# STM32L562xx register map
File version: 1.0
Registers are 32-bit, read-write, reset 0x0 unless marked. A register's access mark holds for its fields unless they carry their own. Offsets are from the block's base; [hi:lo] are bit positions; {n}, {i} and the like mark numbered series; 'fields as' and 'values as' point back to an identical list.

## FMC_Bank1_R — Flexible Memory Controller
Base 0x44020000
Same registers: FMC_Bank1_R_S 0x54020000
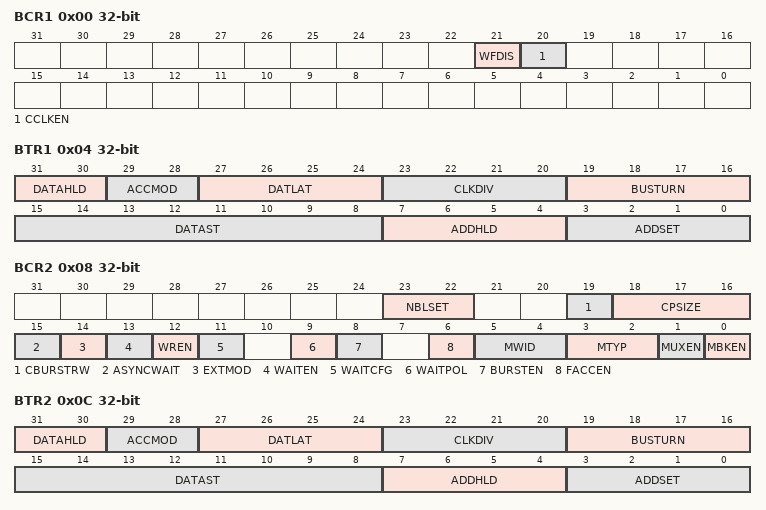
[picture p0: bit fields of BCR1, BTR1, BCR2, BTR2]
0x00 BCR1 — NOR/PSRAM chip-select control register(BCR) and chip-select timing register(BTR)
  [21] WFDIS — Write FIFO Disable
  [20] CCLKEN — Continuous clock enable
0x04 BTR1 — NOR/PSRAM chip-select control register(BCR) and chip-select timing register(BTR)
  [31:30] DATAHLD — DATAHLD[1:0] bits (Data hold phase duration)
  [29:28] ACCMOD — ACCMOD[1:0] bits (Access mode)
  [27:24] DATLAT — DATLAT[3:0] bits (Data latency)
  [23:20] CLKDIV — CLKDIV[3:0] bits (Clock divide ratio)
  [19:16] BUSTURN — BUSTURN[3:0] bits (Bus turnaround phase duration)
  [15:8] DATAST — DATAST [3:0] bits (Data-phase duration)
  [7:4] ADDHLD — ADDHLD[3:0] bits (Address-hold phase duration)
  [3:0] ADDSET — ADDSET[3:0] bits (Address setup phase duration)
0x08 BCR2 — NOR/PSRAM chip-select control register(BCR) and chip-select timing register(BTR)
  [23:22] NBLSET — Byte lane (NBL) setup
  [19] CBURSTRW — Write burst enable
  [18:16] CPSIZE — CRAM page size
  [15] ASYNCWAIT — Asynchronous wait
  [14] EXTMOD — Extended mode enable
  [13] WAITEN — Wait enable bit
  [12] WREN — Write enable bit
  [11] WAITCFG — Wait timing configuration
  [9] WAITPOL — Wait signal polarity bit
  [8] BURSTEN — Burst enable bit
  [6] FACCEN — Flash access enable
  [5:4] MWID — MWID[1:0] bits (Memory data bus width)
  [3:2] MTYP — MTYP[1:0] bits (Memory type)
  [1] MUXEN — Address/data multiplexing enable bit
  [0] MBKEN — Memory bank enable bit
0x0C BTR2 — NOR/PSRAM chip-select control register(BCR) and chip-select timing register(BTR)
  fields as BTR1
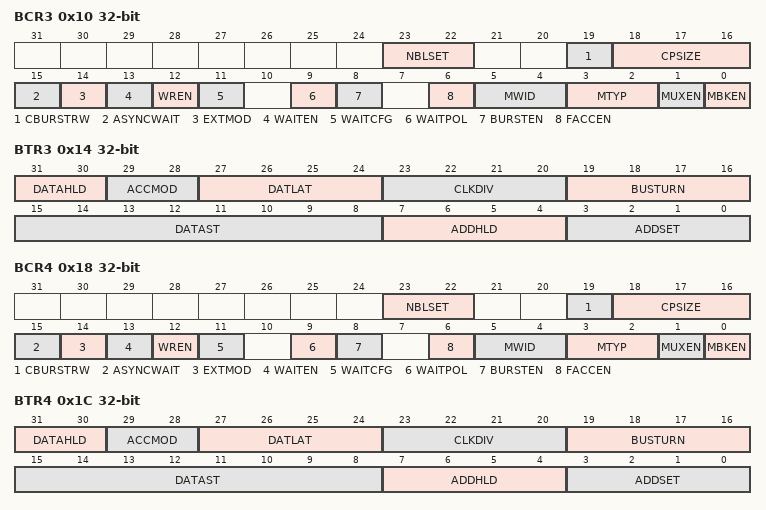
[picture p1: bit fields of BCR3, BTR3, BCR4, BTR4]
0x10 BCR3 — NOR/PSRAM chip-select control register(BCR) and chip-select timing register(BTR)
  fields as BCR2
0x14 BTR3 — NOR/PSRAM chip-select control register(BCR) and chip-select timing register(BTR)
  fields as BTR1
0x18 BCR4 — NOR/PSRAM chip-select control register(BCR) and chip-select timing register(BTR)
  fields as BCR2
0x1C BTR4 — NOR/PSRAM chip-select control register(BCR) and chip-select timing register(BTR)
  fields as BTR1
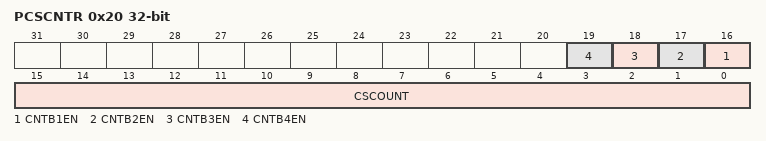
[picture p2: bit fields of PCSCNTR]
0x20 PCSCNTR — PSRAM chip-select counter register
  [n+15] CNTB{n}EN (n=1..4) — Counter PSRAM/NOR Bank1_{n} enable
  [15:0] CSCOUNT — CSCOUNT[15:0] bits (Chip select counter)

## FMC_Bank3_R — Flexible Memory Controller Bank3
Base 0x44020080
Same registers: FMC_Bank3_R_S 0x54020080
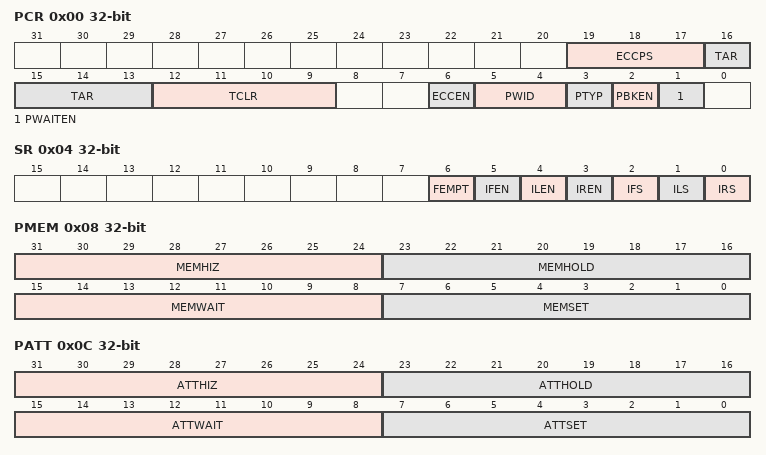
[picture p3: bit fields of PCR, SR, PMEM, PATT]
0x00 PCR — NAND Flash control register
  [19:17] ECCPS — ECCPS[1:0] bits (ECC page size)
  [16:13] TAR — TAR[3:0] bits (ALE to RE delay)
  [12:9] TCLR — TCLR[3:0] bits (CLE to RE delay)
  [6] ECCEN — ECC computation logic enable bit
  [5:4] PWID — PWID[1:0] bits (NAND Flash databus width)
  [3] PTYP — Memory type
  [2] PBKEN — NAND Flash memory bank enable bit
  [1] PWAITEN — Wait feature enable bit
0x04 SR — NAND Flash FIFO status and interrupt register
  [6] FEMPT — FIFO empty
  [5] IFEN — Interrupt Falling Edge detection Enable bit
  [4] ILEN — Interrupt Level detection Enable bit
  [3] IREN — Interrupt Rising Edge detection Enable bit
  [2] IFS — Interrupt Falling Edge status
  [1] ILS — Interrupt Level status
  [0] IRS — Interrupt Rising Edge status
0x08 PMEM — NAND Flash Common memory space timing register
  [31:24] MEMHIZ — MEMHIZ[7:0] bits (Common memory databus HiZ time)
  [23:16] MEMHOLD — MEMHOLD[7:0] bits (Common memory hold time)
  [15:8] MEMWAIT — MEMWAIT[7:0] bits (Common memory wait time)
  [7:0] MEMSET — MEMSET[7:0] bits (Common memory setup time)
0x0C PATT — NAND Flash Attribute memory space timing register
  [31:24] ATTHIZ — ATTHIZ[7:0] bits (Attribute memory databus HiZ time)
  [23:16] ATTHOLD — ATTHOLD[7:0] bits (Attribute memory hold time)
  [15:8] ATTWAIT — ATTWAIT[7:0] bits (Attribute memory wait time)
  [7:0] ATTSET — ATTSET[7:0] bits (Attribute memory setup time)
0x14 ECCR — NAND Flash ECC result registers
  [31:0] ECC — ECC result

## FMC_Bank1E_R — Flexible Memory Controller Bank1E
Base 0x44020104
Same registers: FMC_Bank1E_R_S 0x54020104
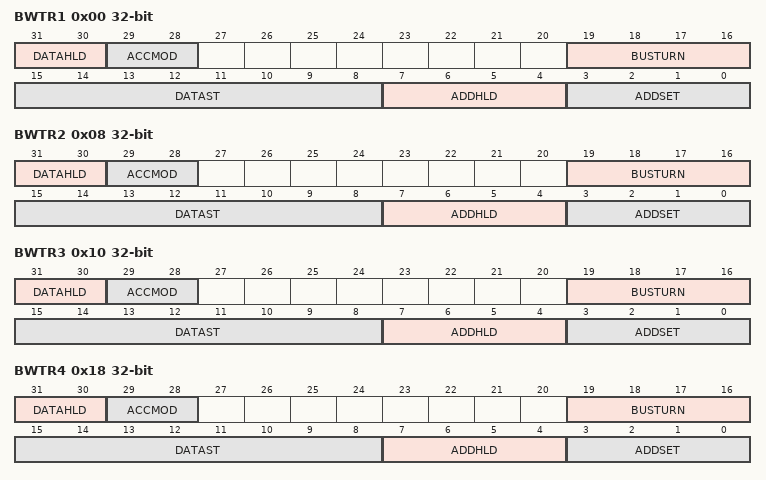
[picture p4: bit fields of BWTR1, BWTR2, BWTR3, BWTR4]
0x00 BWTR1 — NOR/PSRAM write timing registers
  [31:30] DATAHLD — DATAHLD[1:0] bits (Data hold phase duration)
  [29:28] ACCMOD — ACCMOD[1:0] bits (Access mode)
  [19:16] BUSTURN — BUSTURN[3:0] bits (Bus turnaround phase duration)
  [15:8] DATAST — DATAST [3:0] bits (Data-phase duration)
  [7:4] ADDHLD — ADDHLD[3:0] bits (Address-hold phase duration)
  [3:0] ADDSET — ADDSET[3:0] bits (Address setup phase duration)
0x08 BWTR2 — NOR/PSRAM write timing registers
  fields as BWTR1
0x10 BWTR3 — NOR/PSRAM write timing registers
  fields as BWTR1
0x18 BWTR4 — NOR/PSRAM write timing registers
  fields as BWTR1

## DBGMCU — Debug MCU
Base 0xE0044000
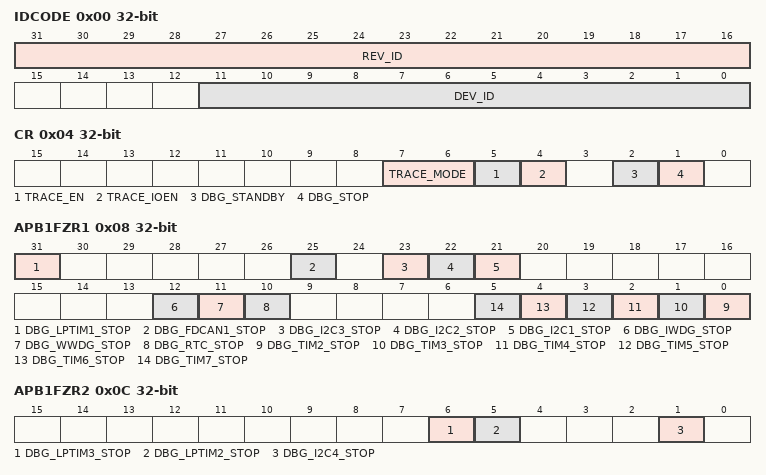
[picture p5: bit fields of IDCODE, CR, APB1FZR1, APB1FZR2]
0x00 IDCODE — MCU device ID code
  [31:16] REV_ID, [11:0] DEV_ID
0x04 CR — Debug MCU configuration register
  [7:6] TRACE_MODE, [5] TRACE_EN, [4] TRACE_IOEN, [2] DBG_STANDBY, [1] DBG_STOP
0x08 APB1FZR1 — Debug MCU APB1 freeze register 1
  [31] DBG_LPTIM1_STOP, [25] DBG_FDCAN1_STOP, [23] DBG_I2C3_STOP, [22] DBG_I2C2_STOP, [21] DBG_I2C1_STOP, [12] DBG_IWDG_STOP, [11] DBG_WWDG_STOP, [10] DBG_RTC_STOP, [n-2] DBG_TIM{n}_STOP (n=2..7)
0x0C APB1FZR2 — Debug MCU APB1 freeze register 2
  [6] DBG_LPTIM3_STOP, [5] DBG_LPTIM2_STOP, [1] DBG_I2C4_STOP
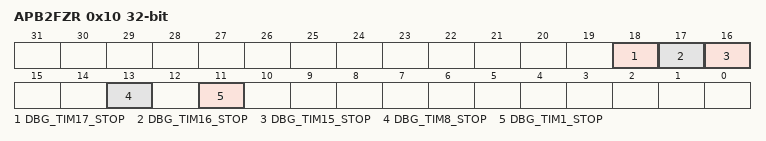
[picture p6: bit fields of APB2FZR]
0x10 APB2FZR — Debug MCU APB2 freeze register
  [18] DBG_TIM17_STOP, [17] DBG_TIM16_STOP, [16] DBG_TIM15_STOP, [13] DBG_TIM8_STOP, [11] DBG_TIM1_STOP
